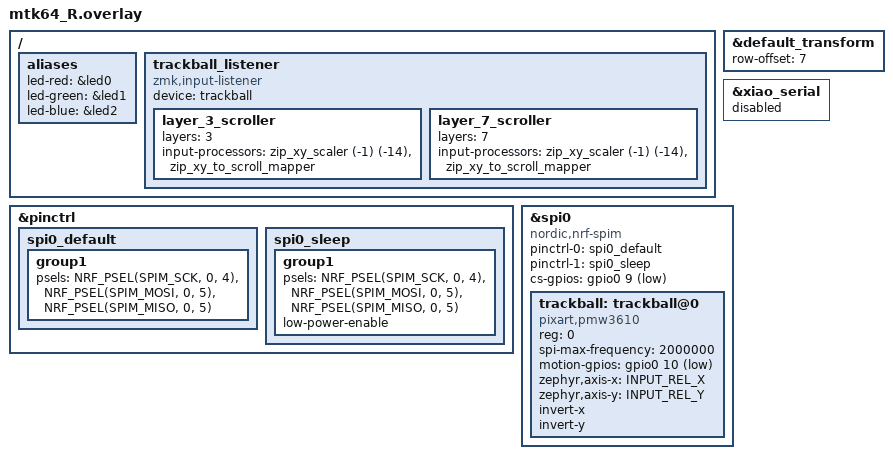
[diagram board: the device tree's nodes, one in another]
#include "mtk64.dtsi"
#include <dt-bindings/input/input-event-codes.h>

&default_transform {
    row-offset = <7>;
};

/ {
    aliases {
        led-red = &led0;
        led-green = &led1;
        led-blue = &led2;
    };
};

/*
&kscan0 {
    gpios
        = <&xiao_d 1 GPIO_ACTIVE_HIGH> 
        , <&xiao_d 2 GPIO_ACTIVE_HIGH> 
        , <&xiao_d 3 GPIO_ACTIVE_HIGH> 
        , <&xiao_d 6 GPIO_ACTIVE_HIGH>
        , <&xiao_d 7 GPIO_ACTIVE_HIGH> 
        , <&xiao_d 8 GPIO_ACTIVE_HIGH> 
        , <&xiao_d 9 GPIO_ACTIVE_HIGH> 	
    ;
};
*/

  / {
      trackball_listener: trackball_listener {
          compatible = "zmk,input-listener";
          device = <&trackball>;

        /* レイヤー3：スクロール（反転） */
        layer_3_scroller {
            layers = <3>;
            input-processors =
            <&zip_xy_scaler (-1) (-14)
            &zip_xy_to_scroll_mapper>;
        };

        /* レイヤー7：スクロール（反転） */
        layer_7_scroller {
            layers = <7>;
            input-processors =
            <&zip_xy_scaler (-1) (-14)
             &zip_xy_to_scroll_mapper>;
          };
      };
  };

&pinctrl {
    spi0_default: spi0_default {
        group1 {
            psels = <NRF_PSEL(SPIM_SCK, 0, 4)>,
                <NRF_PSEL(SPIM_MOSI, 0, 5)>,
                <NRF_PSEL(SPIM_MISO, 0, 5)>;
        };
    };

    spi0_sleep: spi0_sleep {
        group1 {
            psels = <NRF_PSEL(SPIM_SCK, 0, 4)>,
                <NRF_PSEL(SPIM_MOSI, 0, 5)>,
                <NRF_PSEL(SPIM_MISO, 0, 5)>;
            low-power-enable;
        };
    };
};

&xiao_serial { status = "disabled"; };

&spi0 {
    status = "okay";
    compatible = "nordic,nrf-spim";
    pinctrl-0 = <&spi0_default>;
    pinctrl-1 = <&spi0_sleep>;
    pinctrl-names = "default", "sleep";
    cs-gpios = <&gpio0 9 GPIO_ACTIVE_LOW>;

  trackball: trackball@0 {
      status = "okay";
      compatible = "pixart,pmw3610";
      reg = <0>;
      spi-max-frequency = <2000000>;
      motion-gpios = <&gpio0 10 (GPIO_ACTIVE_LOW | GPIO_PULL_UP)>;
      zephyr,axis-x = <INPUT_REL_X>;
      zephyr,axis-y = <INPUT_REL_Y>;
      invert-x;
      invert-y;
    };
};


